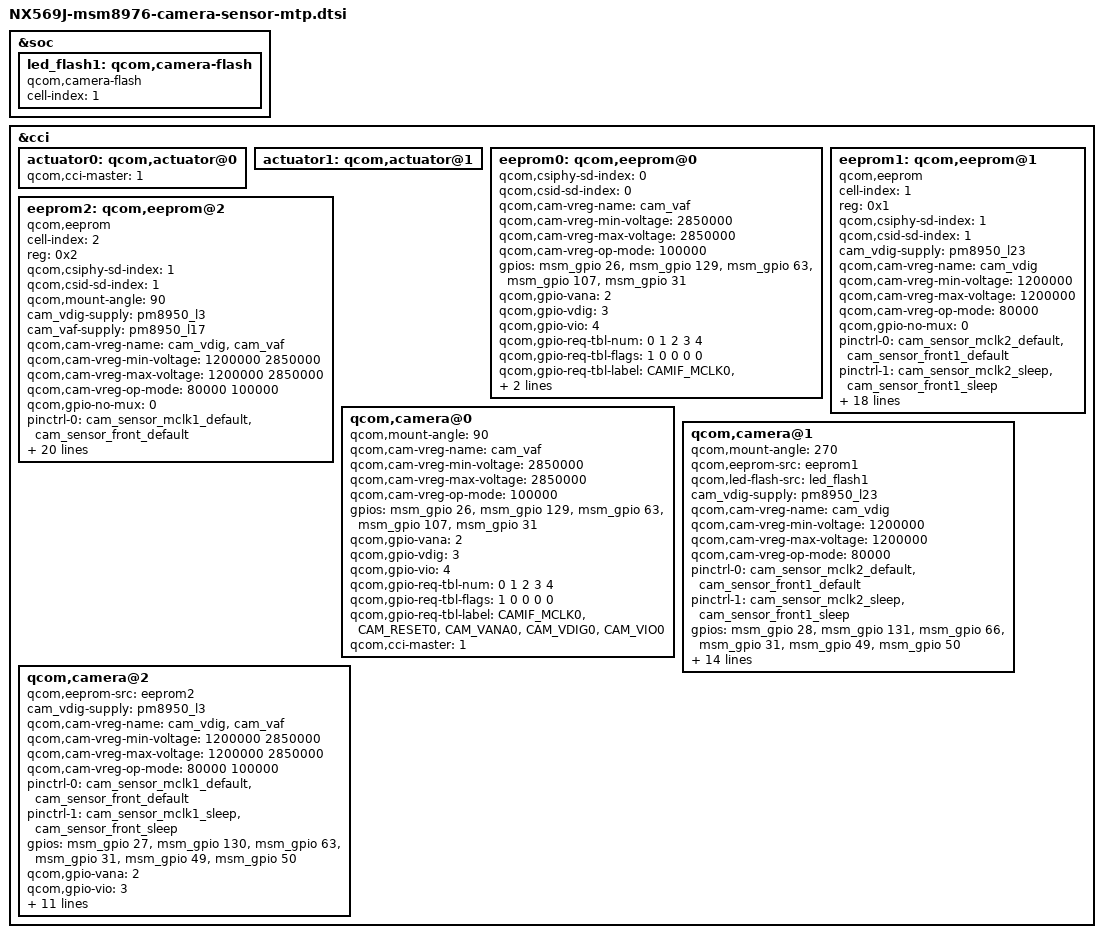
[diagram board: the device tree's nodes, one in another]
/*
 * Copyright (c) 2015-2016, The Linux Foundation. All rights reserved.
 *
 * This program is free software; you can redistribute it and/or modify
 * it under the terms of the GNU General Public License version 2 and
 * only version 2 as published by the Free Software Foundation.
 *
 * This program is distributed in the hope that it will be useful,
 * but WITHOUT ANY WARRANTY; without even the implied warranty of
 * MERCHANTABILITY or FITNESS FOR A PARTICULAR PURPOSE.  See the
 * GNU General Public License for more details.
 */

&soc {
	led_flash1: qcom,camera-flash {
		cell-index = <1>;
		compatible = "qcom,camera-flash";
	};
};
&cci {
	actuator0: qcom,actuator@0 {
		qcom,cci-master = <1>;
		/delete-property/ cam_vaf-supply;
		/delete-property/ qcom,cam-vreg-name;
		/delete-property/ qcom,cam-vreg-min-voltage;
		/delete-property/ qcom,cam-vreg-max-voltage;
		/delete-property/ qcom,cam-vreg-op-mode;
	};
    actuator1: qcom,actuator@1 {
		/delete-property/ cam_vaf-supply;
		/delete-property/ qcom,cam-vreg-name;
		/delete-property/ qcom,cam-vreg-min-voltage;
		/delete-property/ qcom,cam-vreg-max-voltage;
		/delete-property/ qcom,cam-vreg-op-mode;
	};
	
	eeprom0: qcom,eeprom@0 {
		/delete-property/ qcom,cci-master;
		/delete-property/ cam_vdig-supply;
		/delete-property/ cam_vio-supply;
		qcom,csiphy-sd-index = <0>;
		qcom,csid-sd-index = <0>;
		qcom,cam-vreg-name = "cam_vaf";
		qcom,cam-vreg-min-voltage = <2850000>;
		qcom,cam-vreg-max-voltage = <2850000>;
		qcom,cam-vreg-op-mode = <100000>;
		gpios = <&msm_gpio 26 0>,
			<&msm_gpio 129 0>,
			<&msm_gpio 63 0>,
			<&msm_gpio 107 0>,
			<&msm_gpio 31 0>;
		/delete-property/ qcom,gpio-standby;
		qcom,gpio-vana = <2>;
		qcom,gpio-vdig = <3>;
		qcom,gpio-vio = <4>;
		qcom,gpio-req-tbl-num = <0 1 2 3 4>;
		qcom,gpio-req-tbl-flags = <1 0 0 0 0>;
		qcom,gpio-req-tbl-label = "CAMIF_MCLK0",
			"CAM_RESET0",
			"CAM_VANA0",
			"CAM_VDIG0",
			"CAM_VIO0";
		qcom,cci-master = <1>;
   };

	eeprom1: qcom,eeprom@1 {
		cell-index = <1>;
		reg = <0x1>;
		compatible = "qcom,eeprom";
		qcom,csiphy-sd-index = <1>;
		qcom,csid-sd-index = <1>;
		cam_vdig-supply = <&pm8950_l23>;
		qcom,cam-vreg-name = "cam_vdig";
		qcom,cam-vreg-min-voltage = <1200000>;
		qcom,cam-vreg-max-voltage = <1200000>;
		qcom,cam-vreg-op-mode = <80000>;
		qcom,gpio-no-mux = <0>;
		pinctrl-names = "cam_default", "cam_suspend";
		pinctrl-0 = <&cam_sensor_mclk2_default &cam_sensor_front1_default>;
		pinctrl-1 = <&cam_sensor_mclk2_sleep &cam_sensor_front1_sleep>;
		gpios = <&msm_gpio 28 0>,
			<&msm_gpio 131 0>,
			<&msm_gpio 66 0>,
			<&msm_gpio 31 0>,
			<&msm_gpio 49 0>,
			<&msm_gpio 50 0>;
		qcom,gpio-reset = <1>;
		qcom,gpio-vana  = <2>;
		qcom,gpio-vio = <3>;
		qcom,gpio-custom1 = <4>;//mipisw_en
		qcom,gpio-custom2 = <5>;//mipisw_sel
		qcom,gpio-req-tbl-num = <0 1 2 3 4 5>;
		qcom,gpio-req-tbl-flags = <1 0 0 0 0 0>;
		qcom,gpio-req-tbl-label = "CAMIF_MCLK2",
					  "CAM_RESET2",
					  "CAM_VANA2",
					  "CAM_VIO2",
					  "CAM_CUSTOM12",
					  "CAM_CUSTOM22";
		qcom,sensor-position = <1>;
		qcom,sensor-mode = <0>;
		qcom,cci-master = <0>;
		status = "ok";
		clocks = <&clock_gcc clk_mclk2_clk_src>,
			<&clock_gcc clk_gcc_camss_mclk2_clk>;
		clock-names = "cam_src_clk", "cam_clk";
		qcom,clock-rates = <24000000 0>;
	};
    eeprom2: qcom,eeprom@2 {
		cell-index = <2>;
		reg = <0x2>;
		compatible = "qcom,eeprom";
		qcom,csiphy-sd-index = <1>;
		qcom,csid-sd-index = <1>;
		qcom,mount-angle = <90>;
		cam_vdig-supply = <&pm8950_l3>;
		cam_vaf-supply = <&pm8950_l17>;
		qcom,cam-vreg-name = "cam_vdig", "cam_vaf";
		qcom,cam-vreg-min-voltage = <1200000 2850000>;
		qcom,cam-vreg-max-voltage = <1200000 2850000>;
		qcom,cam-vreg-op-mode = <80000 100000>;
		qcom,gpio-no-mux = <0>;
		pinctrl-names = "cam_default", "cam_suspend";
		pinctrl-0 = <&cam_sensor_mclk1_default &cam_sensor_front_default>;
		pinctrl-1 = <&cam_sensor_mclk1_sleep &cam_sensor_front_sleep>;
		gpios = <&msm_gpio 27 0>,
			<&msm_gpio 130 0>,
			<&msm_gpio 63 0>,
			<&msm_gpio 31 0>,
			<&msm_gpio 49 0>,
			<&msm_gpio 50 0>;
		qcom,gpio-reset = <1>;
		qcom,gpio-vana = <2>;
		qcom,gpio-vio = <3>;
		qcom,gpio-custom1 = <4>;//mipisw_en
		qcom,gpio-custom2 = <5>;//mipisw_sel
		qcom,gpio-req-tbl-num = <0 1 2 3 4 5>;
		qcom,gpio-req-tbl-flags = <1 0 0 0 0 0>;
		qcom,gpio-req-tbl-label = "CAMIF_MCLK1",
					  "CAM_RESET1",
					  "CAM_VANA1",
					  "CAM_VIO1",
					  "CAM_CUSTOM11",
					  "CAM_CUSTOM21";
		qcom,sensor-position = <0x100>;
		qcom,sensor-mode = <1>;
		qcom,cci-master = <0>;
		status = "ok";
		clocks = <&clock_gcc clk_mclk1_clk_src>,
				<&clock_gcc clk_gcc_camss_mclk1_clk>;
		clock-names = "cam_src_clk", "cam_clk";
		qcom,clock-rates = <24000000 0>;
	};
	qcom,camera@0 {
		qcom,mount-angle = <90>;
		/delete-property/ cam_vdig-supply;
		/delete-property/ cam_vio-supply;
		/delete-property/ cam_vana-supply;
		qcom,cam-vreg-name = "cam_vaf";
		qcom,cam-vreg-min-voltage = <2850000>;
		qcom,cam-vreg-max-voltage = <2850000>;
		qcom,cam-vreg-op-mode = <100000>;
		gpios = <&msm_gpio 26 0>,
			<&msm_gpio 129 0>,
			<&msm_gpio 63 0>,
			<&msm_gpio 107 0>,
			<&msm_gpio 31 0>;
		/delete-property/ qcom,gpio-standby;
		qcom,gpio-vana = <2>;
		qcom,gpio-vdig = <3>;
		qcom,gpio-vio = <4>;
		qcom,gpio-req-tbl-num = <0 1 2 3 4>;
		qcom,gpio-req-tbl-flags = <1 0 0 0 0>;
		qcom,gpio-req-tbl-label = "CAMIF_MCLK0",
			"CAM_RESET0",
			"CAM_VANA0",
			"CAM_VDIG0",
			"CAM_VIO0";
		qcom,cci-master = <1>;
	};

	qcom,camera@1 {
		qcom,mount-angle = <270>;
		/delete-property/ cam_vio-supply;
		/delete-property/ cam_vana-supply;
		qcom,eeprom-src = <&eeprom1>;
		qcom,led-flash-src = <&led_flash1>;
		cam_vdig-supply = <&pm8950_l23>;
		qcom,cam-vreg-name = "cam_vdig";
		qcom,cam-vreg-min-voltage = <1200000>;
		qcom,cam-vreg-max-voltage = <1200000>;
		qcom,cam-vreg-op-mode = <80000>;
		pinctrl-0 = <&cam_sensor_mclk2_default &cam_sensor_front1_default>;
		pinctrl-1 = <&cam_sensor_mclk2_sleep &cam_sensor_front1_sleep>;
		gpios = <&msm_gpio 28 0>,
			<&msm_gpio 131 0>,
			<&msm_gpio 66 0>,
			<&msm_gpio 31 0>,
			<&msm_gpio 49 0>,
			<&msm_gpio 50 0>;
		/delete-property/ qcom,gpio-standby;
		/delete-property/ qcom,gpio-vdig;
		qcom,gpio-vana  = <2>;
		qcom,gpio-vio = <3>;
		qcom,gpio-custom1 = <4>;//mipisw_en
		qcom,gpio-custom2 = <5>;//mipisw_sel
		qcom,gpio-req-tbl-num = <0 1 2 3 4 5>;
		qcom,gpio-req-tbl-flags = <1 0 0 0 0 0>;
		qcom,gpio-req-tbl-label = "CAMIF_MCLK2",
					  "CAM_RESET2",
					  "CAM_VANA2",
					  "CAM_VIO2",
					  "CAM_CUSTOM12",
					  "CAM_CUSTOM22";
		qcom,sensor-position = <1>;
		qcom,sensor-mode = <0>;
		qcom,cci-master = <0>;
		clocks = <&clock_gcc clk_mclk2_clk_src>,
			<&clock_gcc clk_gcc_camss_mclk2_clk>;
	};
	qcom,camera@2{
		qcom,eeprom-src = <&eeprom2>;
		cam_vdig-supply = <&pm8950_l3>;
		/delete-property/ cam_vana-supply;
		/delete-property/ cam_vio-supply;
		qcom,cam-vreg-name = "cam_vdig", "cam_vaf";
		qcom,cam-vreg-min-voltage = <1200000 2850000>;
		qcom,cam-vreg-max-voltage = <1200000 2850000>;
		qcom,cam-vreg-op-mode = <80000 100000>;
		pinctrl-0 = <&cam_sensor_mclk1_default &cam_sensor_front_default>;
		pinctrl-1 = <&cam_sensor_mclk1_sleep &cam_sensor_front_sleep>;
		gpios = <&msm_gpio 27 0>,
			<&msm_gpio 130 0>,
			<&msm_gpio 63 0>,
			<&msm_gpio 31 0>,
			<&msm_gpio 49 0>,
			<&msm_gpio 50 0>;
		/delete-property/ qcom,gpio-standby;
		qcom,gpio-vana = <2>;
		qcom,gpio-vio = <3>;
		qcom,gpio-custom1 = <4>;//mipisw_en
		qcom,gpio-custom2 = <5>;//mipisw_sel
		qcom,gpio-req-tbl-num = <0 1 2 3 4 5>;
		qcom,gpio-req-tbl-flags = <1 0 0 0 0 0>;
		qcom,gpio-req-tbl-label = "CAMIF_MCLK1",
					  "CAM_RESET1",
					  "CAM_VANA1",
					  "CAM_VIO1",
					  "CAM_CUSTOM11",
					  "CAM_CUSTOM21";
		qcom,sensor-position = <0x100>;
		qcom,sensor-mode = <1>;
		clocks = <&clock_gcc clk_mclk1_clk_src>,
				<&clock_gcc clk_gcc_camss_mclk1_clk>;
	};
};
